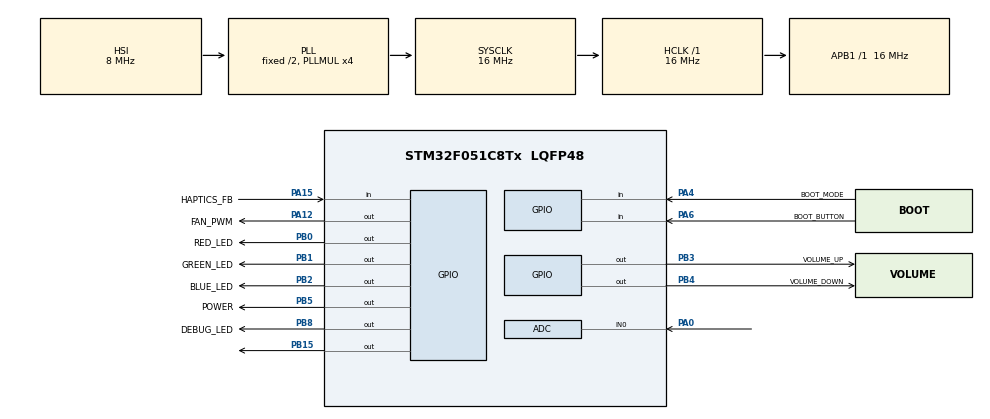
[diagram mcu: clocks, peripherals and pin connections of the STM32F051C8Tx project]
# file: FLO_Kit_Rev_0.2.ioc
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Mcu.Family=STM32F0
Mcu.Name=STM32F051C8Tx
Mcu.Package=LQFP48
PA0.Mode=IN0
PA0.Signal=ADC_IN0
PA12.GPIO_Label=FAN_PWM
PA12.Signal=GPIO_Output
PA13.Mode=Serial_Wire
PA13.Signal=SYS_SWDIO
PA14.Mode=Serial_Wire
PA14.Signal=SYS_SWCLK
PA15.GPIO_Label=HAPTICS_FB
PA15.GPIO_PuPd=GPIO_PULLDOWN
PA15.Signal=GPIO_Input
PA4.GPIO_Label=BOOT_MODE
PA4.Signal=GPIO_Input
PA6.GPIO_Label=BOOT_BUTTON
PA6.GPIO_PuPd=GPIO_PULLUP
PA6.Signal=GPIO_Input
PB0.GPIO_Label=RED_LED
PB0.Signal=GPIO_Output
PB1.GPIO_Label=GREEN_LED
PB1.Signal=GPIO_Output
PB15.Signal=GPIO_Output
PB2.GPIO_Label=BLUE_LED
PB2.Signal=GPIO_Output
PB3.GPIO_Label=VOLUME_UP
PB3.Signal=GPIO_Output
PB4.GPIO_Label=VOLUME_DOWN
PB4.Signal=GPIO_Output
PB5.GPIO_Label=POWER
PB5.Signal=GPIO_Output
PB8.GPIO_Label=DEBUG_LED
PB8.Signal=GPIO_Output
PF0-OSC_IN.Mode=HSE-External-Oscillator
PF0-OSC_IN.Signal=RCC_OSC_IN
PF1-OSC_OUT.Mode=HSE-External-Oscillator
PF1-OSC_OUT.Signal=RCC_OSC_OUT
ProjectManager.HeapSize=0x200
ProjectManager.StackSize=0x400
ProjectManager.TargetToolchain=STM32CubeIDE
RCC.AHBFreq_Value=16000000
RCC.APB1Freq_Value=16000000
RCC.APB1TimFreq_Value=16000000
RCC.HCLKFreq_Value=16000000
RCC.PLLMUL=RCC_PLL_MUL4
RCC.SYSCLKFreq_VALUE=16000000
RCC.SYSCLKSource=RCC_SYSCLKSOURCE_PLLCLK
board=custom

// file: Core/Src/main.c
/* USER CODE BEGIN Header */
/**
  ******************************************************************************
  * @file           : main.c
  * @brief          : Main program body
  ******************************************************************************
  * @attention
  *
  * Copyright (c) 2023 STMicroelectronics.
  * All rights reserved.
  *
  * This software is licensed under terms that can be found in the LICENSE file
  * in the root directory of this software component.
  * If no LICENSE file comes with this software, it is provided AS-IS.
  *
  ******************************************************************************
  */
/* USER CODE END Header */
#include "main.h"

/* USER CODE BEGIN Includes */
#include "flo_edge.h"
/* USER CODE END Includes */

ADC_HandleTypeDef hadc;

void SystemClock_Config(void);
static void MX_GPIO_Init(void);
static void MX_ADC_Init(void);

int main(void)
{

  /* MCU Configuration--------------------------------------------------------*/

  /* Reset of all peripherals, Initializes the Flash interface and the Systick. */
  HAL_Init();

  /* Configure the system clock */
  SystemClock_Config();

  /* Initialize all configured peripherals */
  MX_GPIO_Init();
  MX_ADC_Init();
  /* USER CODE BEGIN 2 */
  flo_edge_init();
  /* USER CODE END 2 */

  /* Infinite loop */
  while (1)
  {

    /* USER CODE BEGIN 3 */
	flo_edge_main();
	  //HAL_GPIO_TogglePin(GPIOA, FAN_PWM_Pin);
	  //HAL_GPIO_WritePin(GPIOA,FAN_PWM_Pin,GPIO_PIN_SET);
//	  if(HAL_GPIO_ReadPin(GPIOA, BOOT_MODE_Pin))
//	  {
//		  HAL_GPIO_WritePin(GPIOB,RED_LED_Pin,GPIO_PIN_RESET);
//	  }
//	  else
//	  {
//		  HAL_GPIO_WritePin(GPIOB,RED_LED_Pin,GPIO_PIN_SET);
//	  }
//	  HAL_GPIO_TogglePin(GPIOB, GREEN_LED_Pin);
////	  HAL_GPIO_TogglePin(GPIOB, VOLUME_UP_Pin);
////	  HAL_GPIO_TogglePin(GPIOB, VOLUME_DOWN_Pin);
////	  HAL_GPIO_TogglePin(GPIOB, POWER_Pin);
//	  HAL_Delay(100);
  }
  /* USER CODE END 3 */
}

void SystemClock_Config(void)
{
  RCC_OscInitTypeDef RCC_OscInitStruct = {0};
  RCC_ClkInitTypeDef RCC_ClkInitStruct = {0};

  /** Initializes the RCC Oscillators according to the specified parameters
  * in the RCC_OscInitTypeDef structure.
  */
  RCC_OscInitStruct.OscillatorType = RCC_OSCILLATORTYPE_HSI|RCC_OSCILLATORTYPE_HSI14;
  RCC_OscInitStruct.HSIState = RCC_HSI_ON;
  RCC_OscInitStruct.HSI14State = RCC_HSI14_ON;
  RCC_OscInitStruct.HSICalibrationValue = RCC_HSICALIBRATION_DEFAULT;
  RCC_OscInitStruct.HSI14CalibrationValue = 16;
  RCC_OscInitStruct.PLL.PLLState = RCC_PLL_ON;
  RCC_OscInitStruct.PLL.PLLSource = RCC_PLLSOURCE_HSI;
  RCC_OscInitStruct.PLL.PLLMUL = RCC_PLL_MUL4;
  RCC_OscInitStruct.PLL.PREDIV = RCC_PREDIV_DIV1;
  if (HAL_RCC_OscConfig(&RCC_OscInitStruct) != HAL_OK)
  {
    Error_Handler();
  }

  /** Initializes the CPU, AHB and APB buses clocks
  */
  RCC_ClkInitStruct.ClockType = RCC_CLOCKTYPE_HCLK|RCC_CLOCKTYPE_SYSCLK
                              |RCC_CLOCKTYPE_PCLK1;
  RCC_ClkInitStruct.SYSCLKSource = RCC_SYSCLKSOURCE_PLLCLK;
  RCC_ClkInitStruct.AHBCLKDivider = RCC_SYSCLK_DIV1;
  RCC_ClkInitStruct.APB1CLKDivider = RCC_HCLK_DIV1;

  if (HAL_RCC_ClockConfig(&RCC_ClkInitStruct, FLASH_LATENCY_0) != HAL_OK)
  {
    Error_Handler();
  }
}

static void MX_ADC_Init(void)
{

  ADC_ChannelConfTypeDef sConfig = {0};

  /** Configure the global features of the ADC (Clock, Resolution, Data Alignment and number of conversion)
  */
  hadc.Instance = ADC1;
  hadc.Init.ClockPrescaler = ADC_CLOCK_ASYNC_DIV1;
  hadc.Init.Resolution = ADC_RESOLUTION_12B;
  hadc.Init.DataAlign = ADC_DATAALIGN_RIGHT;
  hadc.Init.ScanConvMode = ADC_SCAN_DIRECTION_FORWARD;
  hadc.Init.EOCSelection = ADC_EOC_SINGLE_CONV;
  hadc.Init.LowPowerAutoWait = DISABLE;
  hadc.Init.LowPowerAutoPowerOff = DISABLE;
  hadc.Init.ContinuousConvMode = DISABLE;
  hadc.Init.DiscontinuousConvMode = DISABLE;
  hadc.Init.ExternalTrigConv = ADC_SOFTWARE_START;
  hadc.Init.ExternalTrigConvEdge = ADC_EXTERNALTRIGCONVEDGE_NONE;
  hadc.Init.DMAContinuousRequests = DISABLE;
  hadc.Init.Overrun = ADC_OVR_DATA_PRESERVED;
  if (HAL_ADC_Init(&hadc) != HAL_OK)
  {
    Error_Handler();
  }

  /** Configure for the selected ADC regular channel to be converted.
  */
  sConfig.Channel = ADC_CHANNEL_0;
  sConfig.Rank = ADC_RANK_CHANNEL_NUMBER;
  sConfig.SamplingTime = ADC_SAMPLETIME_1CYCLE_5;
  if (HAL_ADC_ConfigChannel(&hadc, &sConfig) != HAL_OK)
  {
    Error_Handler();
  }

}

static void MX_GPIO_Init(void)
{
  GPIO_InitTypeDef GPIO_InitStruct = {0};

  /* GPIO Ports Clock Enable */
  __HAL_RCC_GPIOF_CLK_ENABLE();
  __HAL_RCC_GPIOA_CLK_ENABLE();
  __HAL_RCC_GPIOB_CLK_ENABLE();

  /*Configure GPIO pin Output Level */
  HAL_GPIO_WritePin(GPIOB, RED_LED_Pin|GREEN_LED_Pin|BLUE_LED_Pin|GPIO_PIN_15
                          |VOLUME_UP_Pin|VOLUME_DOWN_Pin|POWER_Pin|DEBUG_LED_Pin, GPIO_PIN_RESET);

  /*Configure GPIO pin Output Level */
  HAL_GPIO_WritePin(FAN_PWM_GPIO_Port, FAN_PWM_Pin, GPIO_PIN_RESET);

  /*Configure GPIO pin : BOOT_MODE_Pin */
  GPIO_InitStruct.Pin = BOOT_MODE_Pin;
  GPIO_InitStruct.Mode = GPIO_MODE_INPUT;
  GPIO_InitStruct.Pull = GPIO_NOPULL;
  HAL_GPIO_Init(BOOT_MODE_GPIO_Port, &GPIO_InitStruct);

  /*Configure GPIO pin : BOOT_BUTTON_Pin */
  GPIO_InitStruct.Pin = BOOT_BUTTON_Pin;
  GPIO_InitStruct.Mode = GPIO_MODE_INPUT;
  GPIO_InitStruct.Pull = GPIO_PULLUP;
  HAL_GPIO_Init(BOOT_BUTTON_GPIO_Port, &GPIO_InitStruct);

  /*Configure GPIO pins : RED_LED_Pin GREEN_LED_Pin BLUE_LED_Pin PB15
                           VOLUME_UP_Pin VOLUME_DOWN_Pin POWER_Pin DEBUG_LED_Pin */
  GPIO_InitStruct.Pin = RED_LED_Pin|GREEN_LED_Pin|BLUE_LED_Pin|GPIO_PIN_15
                          |VOLUME_UP_Pin|VOLUME_DOWN_Pin|POWER_Pin|DEBUG_LED_Pin;
  GPIO_InitStruct.Mode = GPIO_MODE_OUTPUT_PP;
  GPIO_InitStruct.Pull = GPIO_NOPULL;
  GPIO_InitStruct.Speed = GPIO_SPEED_FREQ_LOW;
  HAL_GPIO_Init(GPIOB, &GPIO_InitStruct);

  /*Configure GPIO pin : FAN_PWM_Pin */
  GPIO_InitStruct.Pin = FAN_PWM_Pin;
  GPIO_InitStruct.Mode = GPIO_MODE_OUTPUT_PP;
  GPIO_InitStruct.Pull = GPIO_NOPULL;
  GPIO_InitStruct.Speed = GPIO_SPEED_FREQ_LOW;
  HAL_GPIO_Init(FAN_PWM_GPIO_Port, &GPIO_InitStruct);

  /*Configure GPIO pin : HAPTICS_FB_Pin */
  GPIO_InitStruct.Pin = HAPTICS_FB_Pin;
  GPIO_InitStruct.Mode = GPIO_MODE_INPUT;
  GPIO_InitStruct.Pull = GPIO_PULLDOWN;
  HAL_GPIO_Init(HAPTICS_FB_GPIO_Port, &GPIO_InitStruct);

}

void Error_Handler(void)
{
  __disable_irq();
  while (1)
  {
  }
}
